VERSION ""

NS_ :

BS_:

BU_:

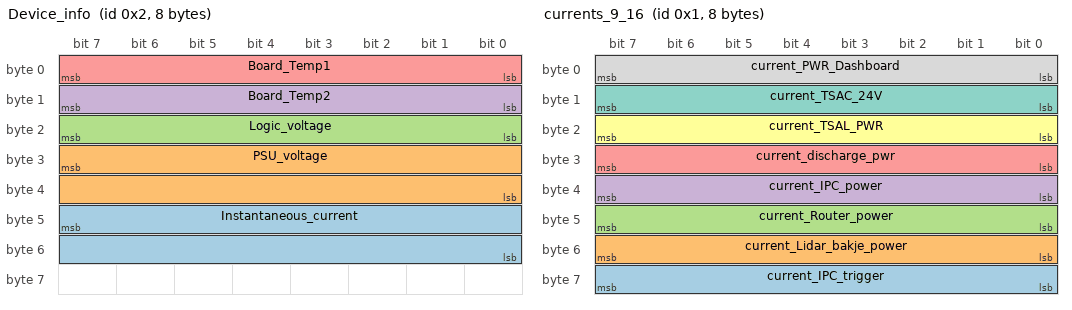
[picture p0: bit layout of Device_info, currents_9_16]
BO_ 2 Device_info: 8 Vector__XXX
 SG_ Instantaneous_current : 47|16@0+ (1,0) [0|255] "" Vector__XXX
 SG_ PSU_voltage : 31|16@0+ (1,0) [0|255] "" Vector__XXX
 SG_ Logic_voltage : 23|8@0+ (1,0) [0|255] "" Vector__XXX
 SG_ Board_Temp2 : 15|8@0+ (1,0) [0|255] "" Vector__XXX
 SG_ Board_Temp1 : 7|8@0+ (1,0) [0|255] "" Vector__XXX

BO_ 1 currents_9_16: 8 Vector__XXX
 SG_ current_IPC_trigger : 63|8@0+ (1,0) [0|255] "" Vector__XXX
 SG_ current_Lidar_bakje_power : 55|8@0+ (1,0) [0|255] "" Vector__XXX
 SG_ current_Router_power : 47|8@0+ (1,0) [0|255] "" Vector__XXX
 SG_ current_IPC_power : 39|8@0+ (1,0) [0|255] "" Vector__XXX
 SG_ current_discharge_pwr : 31|8@0+ (1,0) [0|255] "" Vector__XXX
 SG_ current_TSAL_PWR : 23|8@0+ (1,0) [0|255] "" Vector__XXX
 SG_ current_TSAC_24V : 15|8@0+ (1,0) [0|255] "" Vector__XXX
 SG_ current_PWR_Dashboard : 7|8@0+ (1,0) [0|255] "" Vector__XXX

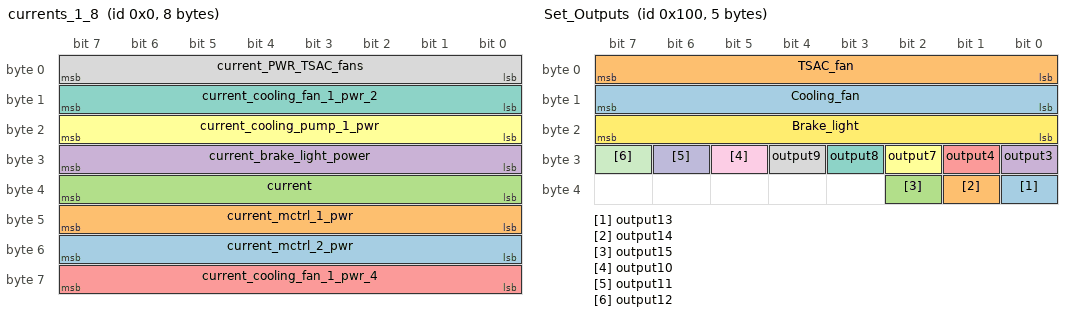
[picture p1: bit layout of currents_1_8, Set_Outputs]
BO_ 0 currents_1_8: 8 Vector__XXX
 SG_ current_mctrl_2_pwr : 55|8@0+ (1,0) [0|255] "" Vector__XXX
 SG_ current_mctrl_1_pwr : 47|8@0+ (1,0) [0|255] "" Vector__XXX
 SG_ current : 39|8@0+ (1,0) [0|255] "" Vector__XXX
 SG_ current_brake_light_power : 31|8@0+ (1,0) [0|255] "" Vector__XXX
 SG_ current_cooling_fan_1_pwr_4 : 56|8@1- (1,0) [0|0] "" Vector__XXX
 SG_ current_cooling_pump_1_pwr : 23|8@0+ (1,0) [0|255] "" Vector__XXX
 SG_ current_cooling_fan_1_pwr_2 : 15|8@0+ (1,0) [0|255] "" Vector__XXX
 SG_ current_PWR_TSAC_fans : 7|8@0+ (1,0) [0|255] "" Vector__XXX

BO_ 258 Output_States: 2 Vector__XXX
 SG_ State : 7|16@0+ (1,0) [0|65535] "" Vector__XXX

BO_ 16 Heartbeat: 0 Vector__XXX

BO_ 257 Inputs: 2 Vector__XXX
 SG_ Watercool_temp2 : 15|8@0+ (1,0) [0|255] "" Vector__XXX
 SG_ Watercool_temp1 : 7|8@0+ (1,0) [0|255] "" Vector__XXX

BO_ 256 Set_Outputs: 5 Vector__XXX
 SG_ output13 : 32|1@0+ (1,0) [0|1] "" Vector__XXX
 SG_ output14 : 33|1@0+ (1,0) [0|1] "" Vector__XXX
 SG_ output15 : 34|1@0+ (1,0) [0|1] "" Vector__XXX
 SG_ output3 : 24|1@0+ (1,0) [0|1] "" Vector__XXX
 SG_ output4 : 25|1@0+ (1,0) [0|1] "" Vector__XXX
 SG_ output7 : 26|1@0+ (1,0) [0|1] "" Vector__XXX
 SG_ output8 : 27|1@0+ (1,0) [0|1] "" Vector__XXX
 SG_ output9 : 28|1@0+ (1,0) [0|1] "" Vector__XXX
 SG_ output10 : 29|1@0+ (1,0) [0|1] "" Vector__XXX
 SG_ output11 : 30|1@0+ (1,0) [0|1] "" Vector__XXX
 SG_ output12 : 31|1@0+ (1,0) [0|1] "" Vector__XXX
 SG_ Brake_light : 23|8@0+ (1,0) [0|255] "" Vector__XXX
 SG_ Cooling_fan : 15|8@0+ (1,0) [0|255] "" Vector__XXX
 SG_ TSAC_fan : 7|8@0+ (1,0) [0|255] "" Vector__XXX

BA_DEF_  "BusType" STRING ;
BA_DEF_DEF_  "BusType" "CAN";
